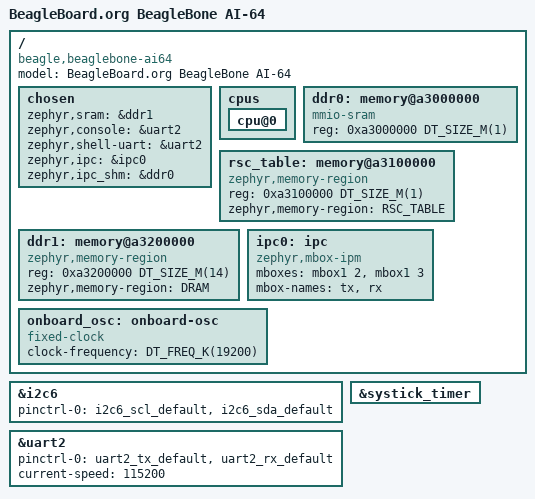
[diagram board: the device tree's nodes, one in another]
/* Copyright (C) 2023 BeagleBoard.org Foundation
 * Copyright (C) 2023 S Prashanth
 * Copyright (c) 2024 Texas Instruments Incorporated
 *	Andrew Davis <afd@ti.com>
 *
 * SPDX-License-Identifier: Apache-2.0
 */

/dts-v1/;

#include <ti/j721e_main_r5.dtsi> /* the real stuff need to study this file in DETAIL !!!!!*/
#include "beaglebone_ai64_j721e_main_r5f0_1-pinctrl.dtsi" /*just defined for xip , uart , console and most importand amp*/
#include <freq.h> /* helper header to make the frequency of clock readable*/

/ {
	model = "BeagleBoard.org BeagleBone AI-64";
	compatible = "beagle,beaglebone-ai64";

	chosen {
		zephyr,sram = &ddr1;
		zephyr,console = &uart2;
		zephyr,shell-uart = &uart2;
		zephyr,ipc = &ipc0;
		zephyr,ipc_shm = &ddr0;
	};
	/* chooses specific peripherals for stuff os needs */
	cpus {
		cpu@0 {
			status = "okay";
		};
	};
	/* status okay just enables everything defined in the soc wala layer*/
	ddr0: memory@a3000000 {
		compatible = "mmio-sram";
		reg = <0xa3000000 DT_SIZE_M(1)>;
	};
	/* ddr0 shared memory between a core and r core , virtio */
	rsc_table: memory@a3100000 {
		compatible = "zephyr,memory-region", "mmio-sram";
		reg = <0xa3100000 DT_SIZE_M(1)>;
		zephyr,memory-region = "RSC_TABLE";
	};
	/* remoteproc table , linux reads this before the r5 core starts to understand the memory structure of this core */
	ddr1: memory@a3200000 {
		compatible = "zephyr,memory-region", "mmio-sram";
		reg = <0xa3200000 DT_SIZE_M(14)>;
		zephyr,memory-region = "DRAM";
	};
	/* stack heap data etc of the r5 core , its private territory*/
	ipc0: ipc {
		compatible = "zephyr,mbox-ipm";
		mboxes = <&mbox1 2>, <&mbox1 3>;
		mbox-names = "tx", "rx";
	};
	/* the number next to &mbox1 is the channel , each cluster shares the mbox so only difference is channel, so core 0 has 0 1 , core 1 has 2 3 */
	onboard_osc: onboard-osc {
		compatible = "fixed-clock";
		clock-frequency = <DT_FREQ_K(19200)>;
		#clock-cells = <0>;
	};
	/*oscillator this is*/
};

&i2c6 {
	status = "okay";
	pinctrl-0 = <&i2c6_scl_default &i2c6_sda_default>;
	pinctrl-names = "default";
};

&uart2 {
	status = "okay";
	pinctrl-0 = <&uart2_tx_default &uart2_rx_default>;
	pinctrl-names = "default";
	current-speed = <115200>;
};

&systick_timer {
	status = "okay";
};
